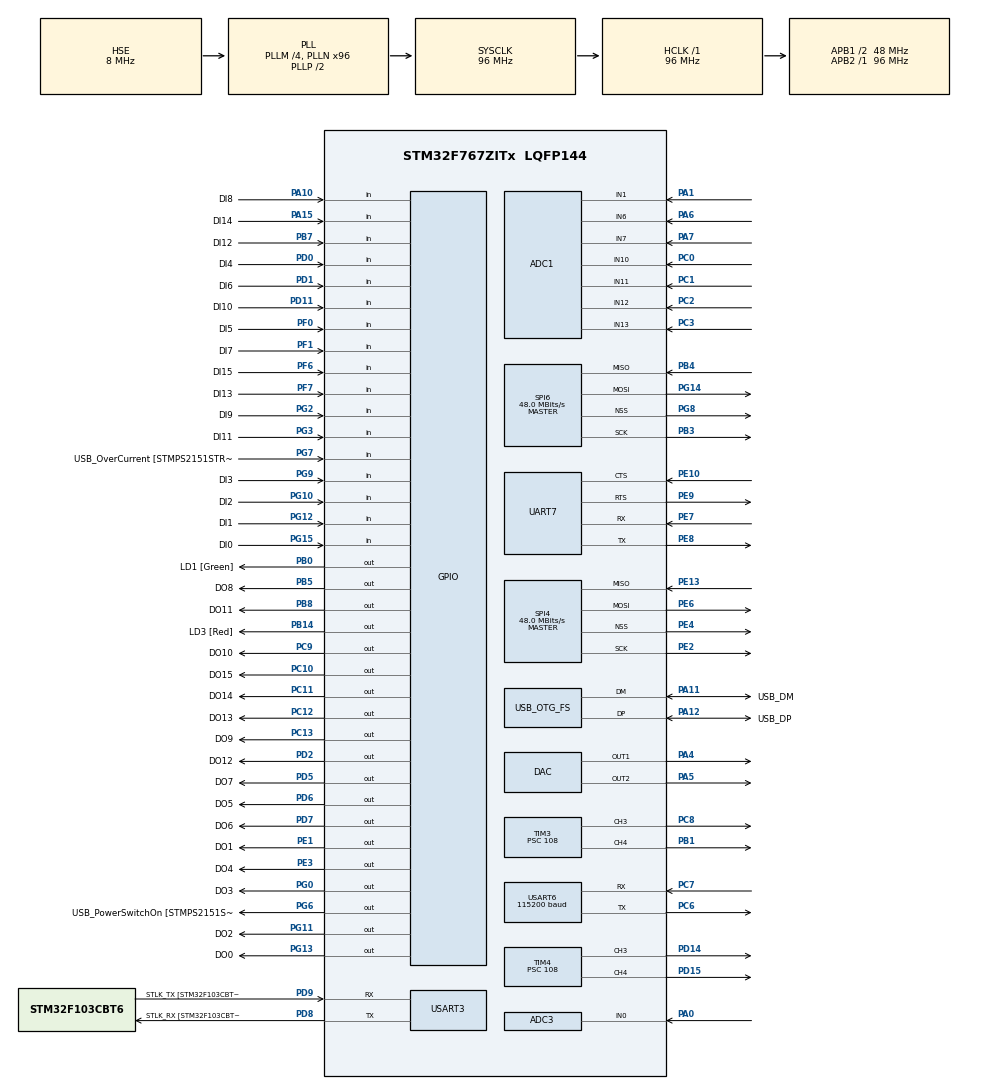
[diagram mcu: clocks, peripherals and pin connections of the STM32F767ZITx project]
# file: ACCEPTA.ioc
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ADC1.Channel-1\#ChannelRegularConversion=ADC_CHANNEL_13
ADC1.ClockPrescaler=ADC_CLOCK_SYNC_PCLK_DIV4
ADC1.NbrOfConversionFlag=1
ADC1.Rank-1\#ChannelRegularConversion=1
ADC1.SamplingTime-1\#ChannelRegularConversion=ADC_SAMPLETIME_3CYCLES
ADC1.master=1
ADC3.Channel-2\#ChannelRegularConversion=ADC_CHANNEL_0
ADC3.ClockPrescaler=ADC_CLOCK_SYNC_PCLK_DIV4
ADC3.NbrOfConversionFlag=1
ADC3.Rank-2\#ChannelRegularConversion=1
ADC3.SamplingTime-2\#ChannelRegularConversion=ADC_SAMPLETIME_3CYCLES
FREERTOS.Tasks01=defaultTask,24,128,StartDefaultTask,Default,NULL,Dynamic,NULL,NULL
FREERTOS.configUSE_NEWLIB_REENTRANT=1
Mcu.Family=STM32F7
Mcu.Name=STM32F767ZITx
Mcu.Package=LQFP144
NVIC.OTG_FS_IRQn=true\:5\:0\:false\:false\:true\:true\:false\:true
NVIC.PriorityGroup=NVIC_PRIORITYGROUP_4
NVIC.TIM8_TRG_COM_TIM14_IRQn=true\:0\:0\:false\:false\:true\:false\:false\:true
NVIC.TimeBase=TIM8_TRG_COM_TIM14_IRQn
NVIC.TimeBaseIP=TIM14
NVIC.USART6_IRQn=true\:5\:0\:false\:false\:true\:true\:true\:true
PA0/WKUP.Signal=ADCx_IN0
PA1.Signal=ADCx_IN1
PA10.GPIO_Label=DI8
PA10.Signal=GPIO_Input
PA11.GPIO_Label=USB_DM
PA11.Mode=Device_Only
PA11.Signal=USB_OTG_FS_DM
PA12.GPIO_Label=USB_DP
PA12.Mode=Device_Only
PA12.Signal=USB_OTG_FS_DP
PA13.Mode=Serial_Wire
PA13.Signal=SYS_JTMS-SWDIO
PA14.Mode=Serial_Wire
PA14.Signal=SYS_JTCK-SWCLK
PA15.GPIO_Label=DI14
PA15.Signal=GPIO_Input
PA4.Signal=COMP_DAC1_group
PA5.Signal=COMP_DAC2_group
PA6.Signal=ADCx_IN6
PA7.Signal=ADCx_IN7
PA8.GPIO_Label=USB_SOF [TP1]
PA8.Signal=USB_OTG_FS_SOF
PA9.GPIO_Label=USB_VBUS
PA9.Signal=USB_OTG_FS_VBUS
PB0.GPIO_Label=LD1 [Green]
PB0.Signal=GPIO_Output
PB1.Signal=S_TIM3_CH4
PB14.GPIO_Label=LD3 [Red]
PB14.Signal=GPIO_Output
PB3.Mode=Full_Duplex_Master
PB3.Signal=SPI6_SCK
PB4.Mode=Full_Duplex_Master
PB4.Signal=SPI6_MISO
PB5.GPIO_Label=DO8
PB5.Signal=GPIO_Output
PB7.GPIO_Label=DI12
PB7.Signal=GPIO_Input
PB8.GPIO_Label=DO11
PB8.Signal=GPIO_Output
PC0.Signal=ADCx_IN10
PC1.Signal=ADCx_IN11
PC10.GPIO_Label=DO15
PC10.Signal=GPIO_Output
PC11.GPIO_Label=DO14
PC11.Signal=GPIO_Output
PC12.GPIO_Label=DO13
PC12.Signal=GPIO_Output
PC13.GPIO_Label=DO9
PC13.Signal=GPIO_Output
PC14/OSC32_IN.Mode=LSE-External-Oscillator
PC14/OSC32_IN.Signal=RCC_OSC32_IN
PC15/OSC32_OUT.Mode=LSE-External-Oscillator
PC15/OSC32_OUT.Signal=RCC_OSC32_OUT
PC2.Signal=ADCx_IN12
PC3.Signal=ADCx_IN13
PC6.Mode=Asynchronous
PC6.Signal=USART6_TX
PC7.Mode=Asynchronous
PC7.Signal=USART6_RX
PC8.Signal=S_TIM3_CH3
PC9.GPIO_Label=DO10
PC9.Signal=GPIO_Output
PD0.GPIO_Label=DI4
PD0.Signal=GPIO_Input
PD1.GPIO_Label=DI6
PD1.Signal=GPIO_Input
PD11.GPIO_Label=DI10
PD11.Signal=GPIO_Input
PD14.Signal=S_TIM4_CH3
PD15.Signal=S_TIM4_CH4
PD2.GPIO_Label=DO12
PD2.Signal=GPIO_Output
PD5.GPIO_Label=DO7
PD5.Signal=GPIO_Output
PD6.GPIO_Label=DO5
PD6.Signal=GPIO_Output
PD7.GPIO_Label=DO6
PD7.Signal=GPIO_Output
PD8.GPIO_Label=STLK_RX [STM32F103CBT6_PA3]
PD8.Mode=Asynchronous
PD8.Signal=USART3_TX
PD9.GPIO_Label=STLK_TX [STM32F103CBT6_PA2]
PD9.Mode=Asynchronous
PD9.Signal=USART3_RX
PE1.GPIO_Label=DO1
PE1.Signal=GPIO_Output
PE10.Mode=CTS_RTS
PE10.Signal=UART7_CTS
PE13.Mode=Full_Duplex_Master
PE13.Signal=SPI4_MISO
PE2.Mode=Full_Duplex_Master
PE2.Signal=SPI4_SCK
PE3.GPIO_Label=DO4
PE3.Signal=GPIO_Output
PE4.Mode=NSS_Signal_Hard_Output
PE4.Signal=SPI4_NSS
PE6.Mode=Full_Duplex_Master
PE6.Signal=SPI4_MOSI
PE7.Mode=Asynchronous
PE7.Signal=UART7_RX
PE8.Mode=Asynchronous
PE8.Signal=UART7_TX
PE9.Mode=CTS_RTS
PE9.Signal=UART7_RTS
PF0.GPIO_Label=DI5
PF0.Signal=GPIO_Input
PF1.GPIO_Label=DI7
PF1.Signal=GPIO_Input
PF6.GPIO_Label=DI15
PF6.Signal=GPIO_Input
PF7.GPIO_Label=DI13
PF7.Signal=GPIO_Input
PG0.GPIO_Label=DO3
PG0.Signal=GPIO_Output
PG10.GPIO_Label=DI2
PG10.Signal=GPIO_Input
PG11.GPIO_Label=DO2
PG11.Signal=GPIO_Output
PG12.GPIO_Label=DI1
PG12.Signal=GPIO_Input
PG13.GPIO_Label=DO0
PG13.Signal=GPIO_Output
PG14.Mode=Full_Duplex_Master
PG14.Signal=SPI6_MOSI
PG15.GPIO_Label=DI0
PG15.Signal=GPIO_Input
PG2.GPIO_Label=DI9
PG2.Signal=GPIO_Input
PG3.GPIO_Label=DI11
PG3.Signal=GPIO_Input
PG6.GPIO_Label=USB_PowerSwitchOn [STMPS2151STR_EN]
PG6.Signal=GPIO_Output
PG7.GPIO_Label=USB_OverCurrent [STMPS2151STR_FAULT]
PG7.Signal=GPIO_Input
PG8.Mode=NSS_Signal_Hard_Output
PG8.Signal=SPI6_NSS
PG9.GPIO_Label=DI3
PG9.Signal=GPIO_Input
PH0/OSC_IN.Mode=HSE-External-Oscillator
PH0/OSC_IN.Signal=RCC_OSC_IN
PH1/OSC_OUT.Mode=HSE-External-Oscillator
PH1/OSC_OUT.Signal=RCC_OSC_OUT
ProjectManager.HeapSize=0x200
ProjectManager.StackSize=0x400
ProjectManager.TargetToolchain=STM32CubeIDE
RCC.48MHZClocksFreq_Value=24000000
RCC.AHBFreq_Value=96000000
RCC.APB1CLKDivider=RCC_HCLK_DIV2
RCC.APB1Freq_Value=48000000
RCC.APB1TimFreq_Value=96000000
RCC.APB2Freq_Value=96000000
RCC.APB2TimFreq_Value=96000000
RCC.CortexFreq_Value=96000000
RCC.HCLKFreq_Value=96000000
RCC.HSE_VALUE=8000000
RCC.HSI_VALUE=16000000
RCC.PLLM=4
RCC.PLLMUL=RCC_PLL_MUL9
RCC.PLLN=96
RCC.PLLQ=4
RCC.PRESCALERUSB=RCC_USBCLKSOURCE_PLL_DIV1_5
RCC.SYSCLKFreq_VALUE=96000000
RCC.SYSCLKSource=RCC_SYSCLKSOURCE_PLLCLK
RCC.SYSCLKSourceVirtual=RCC_SYSCLKSOURCE_PLLCLK
RCC.USBFreq_Value=48000000
RCC.VCOOutputFreq_Value=192000000
SH.ADCx_IN0.0=ADC3_IN0,IN0
SH.ADCx_IN0.1=ADC1_IN0,IN0
SH.ADCx_IN1.0=ADC1_IN1,IN1
SH.ADCx_IN10.0=ADC1_IN10,IN10
SH.ADCx_IN11.0=ADC1_IN11,IN11
SH.ADCx_IN12.0=ADC1_IN12,IN12
SH.ADCx_IN13.0=ADC1_IN13,IN13
SH.ADCx_IN6.0=ADC1_IN6,IN6
SH.ADCx_IN7.0=ADC1_IN7,IN7
SH.COMP_DAC1_group.0=DAC_OUT1,DAC_OUT1
SH.COMP_DAC2_group.0=DAC_OUT2,DAC_OUT2
SH.S_TIM3_CH3.0=TIM3_CH3,PWM Generation3 CH3
SH.S_TIM3_CH4.0=TIM3_CH4,PWM Generation4 CH4
SH.S_TIM4_CH3.0=TIM4_CH3,PWM Generation3 CH3
SH.S_TIM4_CH4.0=TIM4_CH4,PWM Generation4 CH4
SPI4.CalculateBaudRate=48.0 MBits/s
SPI4.Direction=SPI_DIRECTION_2LINES
SPI4.Mode=SPI_MODE_MASTER
SPI4.VirtualNSS=VM_NSSHARD
SPI4.VirtualType=VM_MASTER
SPI6.CalculateBaudRate=48.0 MBits/s
SPI6.Direction=SPI_DIRECTION_2LINES
SPI6.Mode=SPI_MODE_MASTER
SPI6.VirtualNSS=VM_NSSHARD
SPI6.VirtualType=VM_MASTER
TIM3.AutoReloadPreload=TIM_AUTORELOAD_PRELOAD_ENABLE
TIM3.Channel-PWM\ Generation3\ CH3=TIM_CHANNEL_3
TIM3.Channel-PWM\ Generation4\ CH4=TIM_CHANNEL_4
TIM3.Period=20000
TIM3.Prescaler=108
TIM4.AutoReloadPreload=TIM_AUTORELOAD_PRELOAD_ENABLE
TIM4.Channel-PWM\ Generation3\ CH3=TIM_CHANNEL_3
TIM4.Channel-PWM\ Generation4\ CH4=TIM_CHANNEL_4
TIM4.Period=20000
TIM4.Prescaler=108
TIM4.Pulse-PWM\ Generation3\ CH3=0x600
TIM4.Pulse-PWM\ Generation4\ CH4=0x5f0
USART3.VirtualMode-Asynchronous=VM_ASYNC
USART6.BaudRate=115200
USART6.VirtualMode-Asynchronous=VM_ASYNC
USB_DEVICE.CLASS_NAME_FS=HID
USB_DEVICE.PRODUCT_STRING_HID_FS=STM32 KEYBOARD
USB_DEVICE.VirtualMode-HID_FS=Hid
USB_DEVICE.VirtualModeFS=Hid_FS
USB_OTG_FS.VirtualMode=Device_Only
VP_FREERTOS_VS_CMSIS_V2.Mode=CMSIS_V2
VP_SYS_VS_tim14.Mode=TIM14
VP_TIM3_VS_ClockSourceINT.Mode=Internal
VP_TIM4_VS_ClockSourceINT.Mode=Internal
VP_USB_DEVICE_VS_USB_DEVICE_HID_FS.Mode=HID_FS
board=NUCLEO-F767ZI

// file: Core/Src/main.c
/* USER CODE BEGIN Header */
/**
  ******************************************************************************
  * @file           : main.c
  * @brief          : Main program body
  ******************************************************************************
  * @attention
  *
  * <h2><center>&copy; Copyright (c) 2021 STMicroelectronics.
  * All rights reserved.</center></h2>
  *
  * This software component is licensed by ST under Ultimate Liberty license
  * SLA0044, the "License"; You may not use this file except in compliance with
  * the License. You may obtain a copy of the License at:
  *                             www.st.com/SLA0044
  *
  ******************************************************************************
  */
/* USER CODE END Header */
#include "main.h"
#include "cmsis_os.h"
#include "adc.h"
#include "dac.h"
#include "spi.h"
#include "tim.h"
#include "usart.h"
#include "usb_device.h"
#include "gpio.h"

/* USER CODE BEGIN Includes */
#include "main_loop.h"
#include "stm32f767xx.h"
#include "parser/execute_command.h"
/* USER CODE END Includes */

void SystemClock_Config(void);
void MX_FREERTOS_Init(void);

int main(void)
{

  /* MCU Configuration--------------------------------------------------------*/

  /* Reset of all peripherals, Initializes the Flash interface and the Systick. */
  HAL_Init();

  /* Configure the system clock */
  SystemClock_Config();

  /* Initialize all configured peripherals */
  MX_GPIO_Init();
  MX_ADC1_Init();
  MX_ADC3_Init();
  MX_DAC_Init();
  MX_SPI4_Init();
  MX_SPI6_Init();
  MX_TIM4_Init();
  MX_UART7_Init();
  MX_USART3_UART_Init();
  MX_USART6_UART_Init();
  MX_TIM3_Init();
  /* USER CODE BEGIN 2 */

  HAL_TIM_PWM_Start(&htim3, TIM_CHANNEL_3);
  HAL_TIM_PWM_Start(&htim3, TIM_CHANNEL_4);
  HAL_TIM_PWM_Start(&htim4, TIM_CHANNEL_3);
  HAL_TIM_PWM_Start(&htim4, TIM_CHANNEL_4);
  htim4.Instance->CCR3 = 500; // задаем стартовое значение для сервопривода в мкс (ширина импульса) чтобы получить 0 угол
  htim4.Instance->CCR4 = 500; //
  main_loop_create_task();
  //uint8_t data= 9;

  /* USER CODE END 2 */

  /* Init scheduler */
  osKernelInitialize();  /* Call init function for freertos objects (in freertos.c) */
  MX_FREERTOS_Init();
  /* Start scheduler */
  osKernelStart();

  /* We should never get here as control is now taken by the scheduler */
  /* Infinite loop */
  /* USER CODE BEGIN WHILE */
  while (1)
  {
//	  HAL_SPI_Transmit(&hspi4, &data, 1, 1000);
//	  HAL_Delay(2000);
    /* USER CODE END WHILE */

  }
}

void SystemClock_Config(void)
{
  RCC_OscInitTypeDef RCC_OscInitStruct = {0};
  RCC_ClkInitTypeDef RCC_ClkInitStruct = {0};

  /** Configure LSE Drive Capability
  */
  HAL_PWR_EnableBkUpAccess();
  /** Configure the main internal regulator output voltage
  */
  __HAL_RCC_PWR_CLK_ENABLE();
  __HAL_PWR_VOLTAGESCALING_CONFIG(PWR_REGULATOR_VOLTAGE_SCALE3);
  /** Initializes the RCC Oscillators according to the specified parameters
  * in the RCC_OscInitTypeDef structure.
  */
  RCC_OscInitStruct.OscillatorType = RCC_OSCILLATORTYPE_HSE;
  RCC_OscInitStruct.HSEState = RCC_HSE_ON;
  RCC_OscInitStruct.PLL.PLLState = RCC_PLL_ON;
  RCC_OscInitStruct.PLL.PLLSource = RCC_PLLSOURCE_HSE;
  RCC_OscInitStruct.PLL.PLLM = 4;
  RCC_OscInitStruct.PLL.PLLN = 96;
  RCC_OscInitStruct.PLL.PLLP = RCC_PLLP_DIV2;
  RCC_OscInitStruct.PLL.PLLQ = 4;
  RCC_OscInitStruct.PLL.PLLR = 2;
  if (HAL_RCC_OscConfig(&RCC_OscInitStruct) != HAL_OK)
  {
    Error_Handler();
  }
  /** Activate the Over-Drive mode
  */
  if (HAL_PWREx_EnableOverDrive() != HAL_OK)
  {
    Error_Handler();
  }
  /** Initializes the CPU, AHB and APB buses clocks
  */
  RCC_ClkInitStruct.ClockType = RCC_CLOCKTYPE_HCLK|RCC_CLOCKTYPE_SYSCLK
                              |RCC_CLOCKTYPE_PCLK1|RCC_CLOCKTYPE_PCLK2;
  RCC_ClkInitStruct.SYSCLKSource = RCC_SYSCLKSOURCE_PLLCLK;
  RCC_ClkInitStruct.AHBCLKDivider = RCC_SYSCLK_DIV1;
  RCC_ClkInitStruct.APB1CLKDivider = RCC_HCLK_DIV2;
  RCC_ClkInitStruct.APB2CLKDivider = RCC_HCLK_DIV1;

  if (HAL_RCC_ClockConfig(&RCC_ClkInitStruct, FLASH_LATENCY_3) != HAL_OK)
  {
    Error_Handler();
  }
}

void HAL_TIM_PeriodElapsedCallback(TIM_HandleTypeDef *htim)
{
  if (htim->Instance == TIM14) {
    HAL_IncTick();
  }
}

void Error_Handler(void)
{
  __disable_irq();
  while (1)
  {
  }
}

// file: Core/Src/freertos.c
/* USER CODE BEGIN Header */
/**
  ******************************************************************************
  * File Name          : freertos.c
  * Description        : Code for freertos applications
  ******************************************************************************
  * @attention
  *
  * <h2><center>&copy; Copyright (c) 2021 STMicroelectronics.
  * All rights reserved.</center></h2>
  *
  * This software component is licensed by ST under Ultimate Liberty license
  * SLA0044, the "License"; You may not use this file except in compliance with
  * the License. You may obtain a copy of the License at:
  *                             www.st.com/SLA0044
  *
  ******************************************************************************
  */
/* USER CODE END Header */

#include "FreeRTOS.h"
#include "task.h"
#include "main.h"
#include "cmsis_os.h"

/* Definitions for defaultTask */
osThreadId_t defaultTaskHandle;
const osThreadAttr_t defaultTask_attributes = {
  .name = "defaultTask",
  .stack_size = 128 * 4,
  .priority = (osPriority_t) osPriorityNormal,
};

void StartDefaultTask(void *argument);

extern void MX_USB_DEVICE_Init(void);
void MX_FREERTOS_Init(void); /* (MISRA C 2004 rule 8.1) */

void MX_FREERTOS_Init(void) {

  /* Create the thread(s) */
  /* creation of defaultTask */
  defaultTaskHandle = osThreadNew(StartDefaultTask, NULL, &defaultTask_attributes);

}

void StartDefaultTask(void *argument)
{
  /* init code for USB_DEVICE */
  MX_USB_DEVICE_Init();
  for(;;)
  {
    osDelay(1);
  }
}
